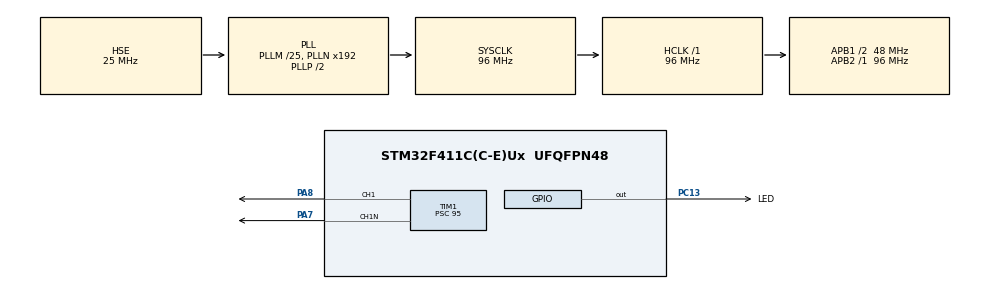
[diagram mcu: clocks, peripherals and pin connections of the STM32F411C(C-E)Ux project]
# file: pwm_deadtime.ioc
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FREERTOS.Tasks01=mainTask,0,128,startMainTask,Default,NULL,Dynamic,NULL,NULL;pwmUpdateTask,-2,128,startPwmUpdateTask,Default,NULL,Dynamic,NULL,NULL
FREERTOS.configGENERATE_RUN_TIME_STATS=1
FREERTOS.configUSE_NEWLIB_REENTRANT=1
Mcu.Family=STM32F4
Mcu.Name=STM32F411C(C-E)Ux
Mcu.Package=UFQFPN48
NVIC.PriorityGroup=NVIC_PRIORITYGROUP_4
NVIC.TIM1_TRG_COM_TIM11_IRQn=true\:5\:0\:false\:false\:true\:false\:false\:true
NVIC.TimeBase=TIM1_TRG_COM_TIM11_IRQn
NVIC.TimeBaseIP=TIM11
PA13.Mode=Serial_Wire
PA13.Signal=SYS_JTMS-SWDIO
PA14.Mode=Serial_Wire
PA14.Signal=SYS_JTCK-SWCLK
PA7.Mode=PWM Generation1 CH1 CH1N
PA7.Signal=TIM1_CH1N
PA8.Signal=S_TIM1_CH1
PC13-ANTI_TAMP.GPIO_Label=LED
PC13-ANTI_TAMP.GPIO_ModeDefaultOutputPP=GPIO_MODE_OUTPUT_OD
PC13-ANTI_TAMP.PinState=GPIO_PIN_SET
PC13-ANTI_TAMP.Signal=GPIO_Output
PH0\ -\ OSC_IN.Mode=HSE-External-Oscillator
PH0\ -\ OSC_IN.Signal=RCC_OSC_IN
PH1\ -\ OSC_OUT.Mode=HSE-External-Oscillator
PH1\ -\ OSC_OUT.Signal=RCC_OSC_OUT
ProjectManager.HeapSize=0x200
ProjectManager.StackSize=0x400
ProjectManager.TargetToolchain=STM32CubeIDE
RCC.48MHZClocksFreq_Value=48000000
RCC.AHBFreq_Value=96000000
RCC.APB1CLKDivider=RCC_HCLK_DIV2
RCC.APB1Freq_Value=48000000
RCC.APB1TimFreq_Value=96000000
RCC.APB2Freq_Value=96000000
RCC.APB2TimFreq_Value=96000000
RCC.CortexFreq_Value=96000000
RCC.HCLKFreq_Value=96000000
RCC.HSE_VALUE=25000000
RCC.HSI_VALUE=16000000
RCC.LSE_VALUE=32768
RCC.PLLM=25
RCC.PLLSourceVirtual=RCC_PLLSOURCE_HSE
RCC.SYSCLKFreq_VALUE=96000000
RCC.SYSCLKSource=RCC_SYSCLKSOURCE_PLLCLK
RCC.VCOOutputFreq_Value=192000000
SH.S_TIM1_CH1.0=TIM1_CH1,PWM Generation1 CH1 CH1N
TIM1.AutomaticOutput=TIM_AUTOMATICOUTPUT_ENABLE
TIM1.BreakState=TIM_BREAK_DISABLE
TIM1.Channel-PWM\ Generation1\ CH1\ CH1N=TIM_CHANNEL_1
TIM1.DeadTime=0
TIM1.LockLevel=TIM_LOCKLEVEL_OFF
TIM1.OC1Preload_PWM=ENABLE
TIM1.OffStateIDLEMode=TIM_OSSI_ENABLE
TIM1.OffStateRunMode=TIM_OSSR_ENABLE
TIM1.Period=999
TIM1.Prescaler=95
TIM1.Pulse-PWM\ Generation1\ CH1\ CH1N=200
TIM1.TIM_MasterOutputTrigger=TIM_TRGO_RESET
VP_FREERTOS_VS_CMSIS_V1.Mode=CMSIS_V1
VP_SYS_VS_tim11.Mode=TIM11
VP_TIM1_VS_ClockSourceINT.Mode=Internal
board=custom

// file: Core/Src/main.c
/* USER CODE BEGIN Header */
/**
  ******************************************************************************
  * @file           : main.c
  * @brief          : Main program body
  ******************************************************************************
  * @attention
  *
  * <h2><center>&copy; Copyright (c) 2021 STMicroelectronics.
  * All rights reserved.</center></h2>
  *
  * This software component is licensed by ST under BSD 3-Clause license,
  * the "License"; You may not use this file except in compliance with the
  * License. You may obtain a copy of the License at:
  *                        opensource.org/licenses/BSD-3-Clause
  *
  ******************************************************************************
  */
/* USER CODE END Header */
#include "main.h"
#include "cmsis_os.h"

TIM_HandleTypeDef htim1;

osThreadId mainTaskHandle;
osThreadId pwmUpdateTaskHandle;

void SystemClock_Config(void);
static void MX_GPIO_Init(void);
static void MX_TIM1_Init(void);
void startMainTask(void const * argument);
void startPwmUpdateTask(void const * argument);

int main(void)
{

  /* MCU Configuration--------------------------------------------------------*/

  /* Reset of all peripherals, Initializes the Flash interface and the Systick. */
  HAL_Init();

  /* Configure the system clock */
  SystemClock_Config();

  /* Initialize all configured peripherals */
  MX_GPIO_Init();
  MX_TIM1_Init();
  /* USER CODE BEGIN 2 */

	// Fire up the PWM timer
	HAL_TIM_PWM_Start(&htim1, TIM_CHANNEL_1);
	HAL_TIMEx_PWMN_Start(&htim1, TIM_CHANNEL_1);

  /* USER CODE END 2 */

  /* Create the thread(s) */
  /* definition and creation of mainTask */
  osThreadDef(mainTask, startMainTask, osPriorityNormal, 0, 128);
  mainTaskHandle = osThreadCreate(osThread(mainTask), NULL);

  /* definition and creation of pwmUpdateTask */
  osThreadDef(pwmUpdateTask, startPwmUpdateTask, osPriorityLow, 0, 128);
  pwmUpdateTaskHandle = osThreadCreate(osThread(pwmUpdateTask), NULL);

  /* Start scheduler */
  osKernelStart();

  /* We should never get here as control is now taken by the scheduler */
  /* Infinite loop */
  while (1)
  {

  }
}

void SystemClock_Config(void)
{
  RCC_OscInitTypeDef RCC_OscInitStruct = {0};
  RCC_ClkInitTypeDef RCC_ClkInitStruct = {0};

  /** Configure the main internal regulator output voltage
  */
  __HAL_RCC_PWR_CLK_ENABLE();
  __HAL_PWR_VOLTAGESCALING_CONFIG(PWR_REGULATOR_VOLTAGE_SCALE1);
  /** Initializes the RCC Oscillators according to the specified parameters
  * in the RCC_OscInitTypeDef structure.
  */
  RCC_OscInitStruct.OscillatorType = RCC_OSCILLATORTYPE_HSE;
  RCC_OscInitStruct.HSEState = RCC_HSE_ON;
  RCC_OscInitStruct.PLL.PLLState = RCC_PLL_ON;
  RCC_OscInitStruct.PLL.PLLSource = RCC_PLLSOURCE_HSE;
  RCC_OscInitStruct.PLL.PLLM = 25;
  RCC_OscInitStruct.PLL.PLLN = 192;
  RCC_OscInitStruct.PLL.PLLP = RCC_PLLP_DIV2;
  RCC_OscInitStruct.PLL.PLLQ = 4;
  if (HAL_RCC_OscConfig(&RCC_OscInitStruct) != HAL_OK)
  {
    Error_Handler();
  }
  /** Initializes the CPU, AHB and APB buses clocks
  */
  RCC_ClkInitStruct.ClockType = RCC_CLOCKTYPE_HCLK|RCC_CLOCKTYPE_SYSCLK
                              |RCC_CLOCKTYPE_PCLK1|RCC_CLOCKTYPE_PCLK2;
  RCC_ClkInitStruct.SYSCLKSource = RCC_SYSCLKSOURCE_PLLCLK;
  RCC_ClkInitStruct.AHBCLKDivider = RCC_SYSCLK_DIV1;
  RCC_ClkInitStruct.APB1CLKDivider = RCC_HCLK_DIV2;
  RCC_ClkInitStruct.APB2CLKDivider = RCC_HCLK_DIV1;

  if (HAL_RCC_ClockConfig(&RCC_ClkInitStruct, FLASH_LATENCY_3) != HAL_OK)
  {
    Error_Handler();
  }
}

static void MX_TIM1_Init(void)
{

  TIM_ClockConfigTypeDef sClockSourceConfig = {0};
  TIM_MasterConfigTypeDef sMasterConfig = {0};
  TIM_OC_InitTypeDef sConfigOC = {0};
  TIM_BreakDeadTimeConfigTypeDef sBreakDeadTimeConfig = {0};

  htim1.Instance = TIM1;
  htim1.Init.Prescaler = 95;
  htim1.Init.CounterMode = TIM_COUNTERMODE_UP;
  htim1.Init.Period = 999;
  htim1.Init.ClockDivision = TIM_CLOCKDIVISION_DIV1;
  htim1.Init.RepetitionCounter = 0;
  htim1.Init.AutoReloadPreload = TIM_AUTORELOAD_PRELOAD_DISABLE;
  if (HAL_TIM_Base_Init(&htim1) != HAL_OK)
  {
    Error_Handler();
  }
  sClockSourceConfig.ClockSource = TIM_CLOCKSOURCE_INTERNAL;
  if (HAL_TIM_ConfigClockSource(&htim1, &sClockSourceConfig) != HAL_OK)
  {
    Error_Handler();
  }
  if (HAL_TIM_PWM_Init(&htim1) != HAL_OK)
  {
    Error_Handler();
  }
  sMasterConfig.MasterOutputTrigger = TIM_TRGO_RESET;
  sMasterConfig.MasterSlaveMode = TIM_MASTERSLAVEMODE_DISABLE;
  if (HAL_TIMEx_MasterConfigSynchronization(&htim1, &sMasterConfig) != HAL_OK)
  {
    Error_Handler();
  }
  sConfigOC.OCMode = TIM_OCMODE_PWM1;
  sConfigOC.Pulse = 200;
  sConfigOC.OCPolarity = TIM_OCPOLARITY_HIGH;
  sConfigOC.OCNPolarity = TIM_OCNPOLARITY_HIGH;
  sConfigOC.OCFastMode = TIM_OCFAST_DISABLE;
  sConfigOC.OCIdleState = TIM_OCIDLESTATE_RESET;
  sConfigOC.OCNIdleState = TIM_OCNIDLESTATE_RESET;
  if (HAL_TIM_PWM_ConfigChannel(&htim1, &sConfigOC, TIM_CHANNEL_1) != HAL_OK)
  {
    Error_Handler();
  }
  sBreakDeadTimeConfig.OffStateRunMode = TIM_OSSR_ENABLE;
  sBreakDeadTimeConfig.OffStateIDLEMode = TIM_OSSI_ENABLE;
  sBreakDeadTimeConfig.LockLevel = TIM_LOCKLEVEL_OFF;
  sBreakDeadTimeConfig.DeadTime = 0;
  sBreakDeadTimeConfig.BreakState = TIM_BREAK_DISABLE;
  sBreakDeadTimeConfig.BreakPolarity = TIM_BREAKPOLARITY_HIGH;
  sBreakDeadTimeConfig.AutomaticOutput = TIM_AUTOMATICOUTPUT_ENABLE;
  if (HAL_TIMEx_ConfigBreakDeadTime(&htim1, &sBreakDeadTimeConfig) != HAL_OK)
  {
    Error_Handler();
  }
  HAL_TIM_MspPostInit(&htim1);

}

static void MX_GPIO_Init(void)
{
  GPIO_InitTypeDef GPIO_InitStruct = {0};

  /* GPIO Ports Clock Enable */
  __HAL_RCC_GPIOC_CLK_ENABLE();
  __HAL_RCC_GPIOH_CLK_ENABLE();
  __HAL_RCC_GPIOA_CLK_ENABLE();

  /*Configure GPIO pin Output Level */
  HAL_GPIO_WritePin(LED_GPIO_Port, LED_Pin, GPIO_PIN_SET);

  /*Configure GPIO pin : LED_Pin */
  GPIO_InitStruct.Pin = LED_Pin;
  GPIO_InitStruct.Mode = GPIO_MODE_OUTPUT_OD;
  GPIO_InitStruct.Pull = GPIO_NOPULL;
  GPIO_InitStruct.Speed = GPIO_SPEED_FREQ_LOW;
  HAL_GPIO_Init(LED_GPIO_Port, &GPIO_InitStruct);

}

void startMainTask(void const * argument)
{
  /* USER CODE BEGIN 5 */

  /* Infinite loop */
  for(;;)
  {
	HAL_GPIO_TogglePin(LED_GPIO_Port, LED_Pin);
    osDelay(100);
  }
  /* USER CODE END 5 */
}

void startPwmUpdateTask(void const * argument)
{
  /* USER CODE BEGIN startPwmUpdateTask */

	uint32_t pwmValue = 100;
	uint32_t pwmChange = 1;

  /* Infinite loop */
  for(;;)
  {
    osDelay(1);
    __HAL_TIM_SET_COMPARE(&htim1, TIM_CHANNEL_1, pwmValue);
    pwmValue += pwmChange;
    if (pwmValue <= 100) pwmChange = 1;
    if (pwmValue >= 900) pwmChange = -1;
  }
  /* USER CODE END startPwmUpdateTask */
}

void HAL_TIM_PeriodElapsedCallback(TIM_HandleTypeDef *htim)
{
  if (htim->Instance == TIM11) {
    HAL_IncTick();
  }
}

void Error_Handler(void)
{
  __disable_irq();
  while (1)
  {
  }
}

/************************ (C) COPYRIGHT STMicroelectronics *****END OF FILE****/
